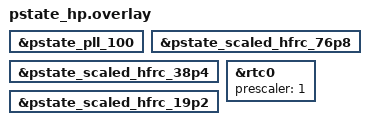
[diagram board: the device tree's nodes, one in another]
/*
 * SoC dtsi has the full PLL + HFRC menu (boot PLL okay, rest disabled).
 * Enable the demo subset. Walk is DT child order.
 */
&pstate_pll_100 {
	status = "okay";
};

&pstate_scaled_hfrc_76p8 {
	status = "okay";
};

&pstate_scaled_hfrc_38p4 {
	status = "okay";
};

&pstate_scaled_hfrc_19p2 {
	status = "okay";
};

/* RTC is the only up-counter; same wall-clock as HE. */
&rtc0 {
	prescaler = <1>;
	status = "okay";
};
